# STM32F411 register map
File version: 1.5
Registers are 32-bit, read-write, reset 0x0 unless marked. A register's access mark holds for its fields unless they carry their own. Offsets are from the block's base; [hi:lo] are bit positions; {n}, {i} and the like mark numbered series.

## TIM2 — General purpose timers
Base 0x40000000
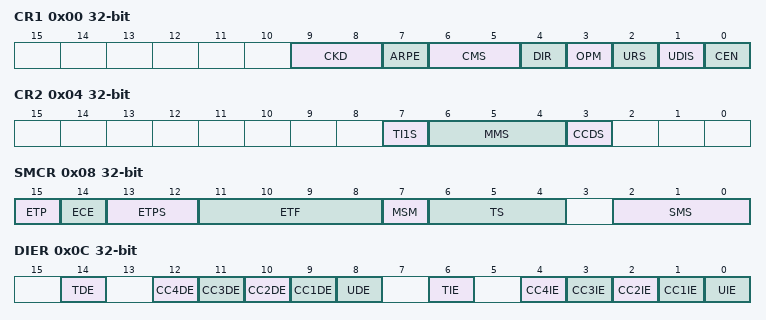
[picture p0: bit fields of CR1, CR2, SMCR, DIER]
0x00 CR1 — control register 1
  [9:8] CKD — Clock division
  [7] ARPE — Auto-reload preload enable
  [6:5] CMS — Center-aligned mode selection
  [4] DIR — Direction
  [3] OPM — One-pulse mode
  [2] URS — Update request source
  [1] UDIS — Update disable
  [0] CEN — Counter enable
0x04 CR2 — control register 2
  [7] TI1S — TI1 selection
  [6:4] MMS — Master mode selection
  [3] CCDS — Capture/compare DMA selection
0x08 SMCR — slave mode control register
  [15] ETP — External trigger polarity
  [14] ECE — External clock enable
  [13:12] ETPS — External trigger prescaler
  [11:8] ETF — External trigger filter
  [7] MSM — Master/Slave mode
  [6:4] TS — Trigger selection
  [2:0] SMS — Slave mode selection
0x0C DIER — DMA/Interrupt enable register
  [14] TDE — Trigger DMA request enable
  [n+8] CC{n}DE (n=1..4) — Capture/Compare {n} DMA request enable
  [8] UDE — Update DMA request enable
  [6] TIE — Trigger interrupt enable
  [n] CC{n}IE (n=1..4) — Capture/Compare {n} interrupt enable
  [0] UIE — Update interrupt enable
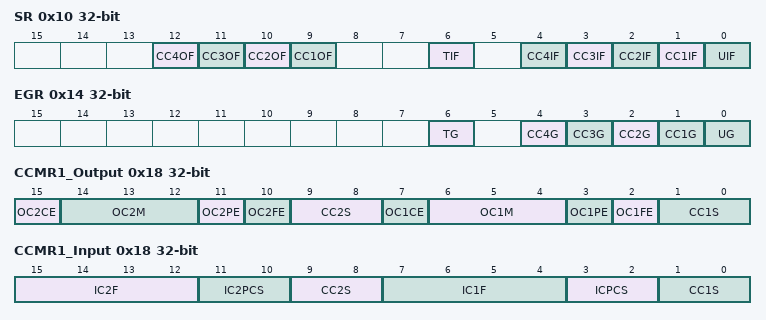
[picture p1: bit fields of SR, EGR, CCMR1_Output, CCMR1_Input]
0x10 SR — status register
  [12] CC4OF — Capture/Compare 4 overcapture flag
  [11] CC3OF — Capture/Compare 3 overcapture flag
  [10] CC2OF — Capture/compare 2 overcapture flag
  [9] CC1OF — Capture/Compare 1 overcapture flag
  [6] TIF — Trigger interrupt flag
  [4] CC4IF — Capture/Compare 4 interrupt flag
  [3] CC3IF — Capture/Compare 3 interrupt flag
  [2] CC2IF — Capture/Compare 2 interrupt flag
  [1] CC1IF — Capture/compare 1 interrupt flag
  [0] UIF — Update interrupt flag
0x14 EGR wo — event generation register
  [6] TG — Trigger generation
  [n] CC{n}G (n=1..4) — Capture/compare {n} generation
  [0] UG — Update generation
0x18 CCMR1_Output — capture/compare mode register 1 (output mode)
  [15] OC2CE, [14:12] OC2M, [11] OC2PE, [10] OC2FE, [9:8] CC2S, [7] OC1CE, [6:4] OC1M, [3] OC1PE, [2] OC1FE, [1:0] CC1S
0x18 CCMR1_Input (alternate view of CCMR1_Output) — capture/compare mode register 1 (input mode)
  [15:12] IC2F — Input capture 2 filter
  [11:10] IC2PCS — Input capture 2 prescaler
  [9:8] CC2S — Capture/Compare 2 selection
  [7:4] IC1F — Input capture 1 filter
  [3:2] ICPCS — Input capture 1 prescaler
  [1:0] CC1S — Capture/Compare 1 selection
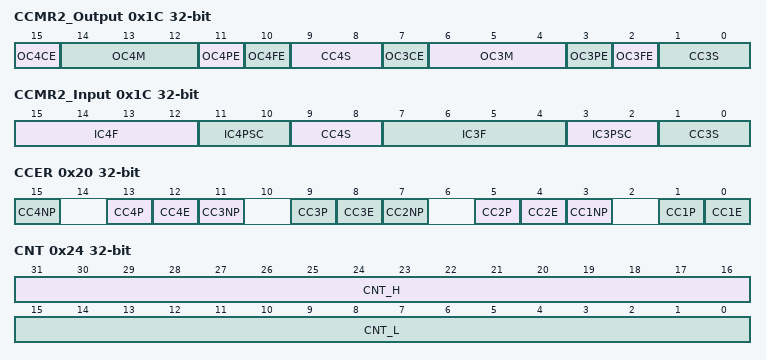
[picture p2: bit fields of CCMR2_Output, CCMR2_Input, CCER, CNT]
0x1C CCMR2_Output — capture/compare mode register 2 (output mode)
  [15] OC4CE, [14:12] OC4M, [11] OC4PE, [10] OC4FE, [9:8] CC4S, [7] OC3CE, [6:4] OC3M, [3] OC3PE, [2] OC3FE, [1:0] CC3S
0x1C CCMR2_Input (alternate view of CCMR2_Output) — capture/compare mode register 2 (input mode)
  [15:12] IC4F — Input capture 4 filter
  [11:10] IC4PSC — Input capture 4 prescaler
  [9:8] CC4S — Capture/Compare 4 selection
  [7:4] IC3F — Input capture 3 filter
  [3:2] IC3PSC — Input capture 3 prescaler
  [1:0] CC3S — Capture/compare 3 selection
0x20 CCER — capture/compare enable register
  [4n-1] CC{n}NP (n=1..4) — Capture/Compare {n} output Polarity
  [13] CC4P — Capture/Compare 3 output Polarity
  [4n-4] CC{n}E (n=1..4) — Capture/Compare {n} output enable
  [9] CC3P — Capture/Compare 3 output Polarity
  [5] CC2P — Capture/Compare 2 output Polarity
  [1] CC1P — Capture/Compare 1 output Polarity
0x24 CNT — counter
  [31:16] CNT_H — High counter value
  [15:0] CNT_L — Low counter value
0x28 PSC — prescaler
  [15:0] PSC — Prescaler value
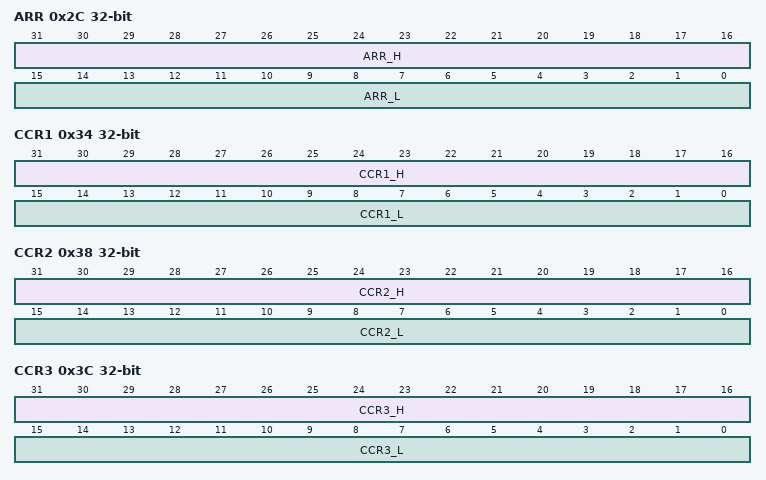
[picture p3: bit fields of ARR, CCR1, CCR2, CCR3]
0x2C ARR — auto-reload register
  [31:16] ARR_H — High Auto-reload value
  [15:0] ARR_L — Low Auto-reload value
0x34 CCR1 — capture/compare register 1
  [31:16] CCR1_H — High Capture/Compare 1 value
  [15:0] CCR1_L — Low Capture/Compare 1 value
0x38 CCR2 — capture/compare register 2
  [31:16] CCR2_H — High Capture/Compare 2 value
  [15:0] CCR2_L — Low Capture/Compare 2 value
0x3C CCR3 — capture/compare register 3
  [31:16] CCR3_H — High Capture/Compare value
  [15:0] CCR3_L — Low Capture/Compare value
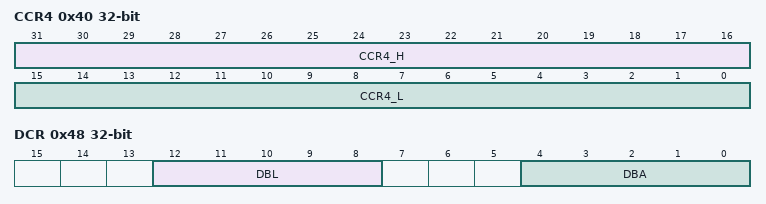
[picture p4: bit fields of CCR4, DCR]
0x40 CCR4 — capture/compare register 4
  [31:16] CCR4_H — High Capture/Compare value
  [15:0] CCR4_L — Low Capture/Compare value
0x48 DCR — DMA control register
  [12:8] DBL — DMA burst length
  [4:0] DBA — DMA base address
0x4C DMAR — DMA address for full transfer
  [15:0] DMAB — DMA register for burst accesses
0x50 OR — TIM5 option register
  [11:10] ITR1_RMP — Timer Input 4 remap

## TIM3 — General purpose timers
Base 0x40000400
Same registers: TIM4 0x40000800
Registers as TIM2, without OR.

## TIM5 — General-purpose-timers
Base 0x40000C00
Registers as TIM2; these are added or differ:
0x50 OR — TIM5 option register
  [7:6] IT4_RMP — Timer Input 4 remap

## USART1 — Universal synchronous asynchronous receiver transmitter
Base 0x40011000
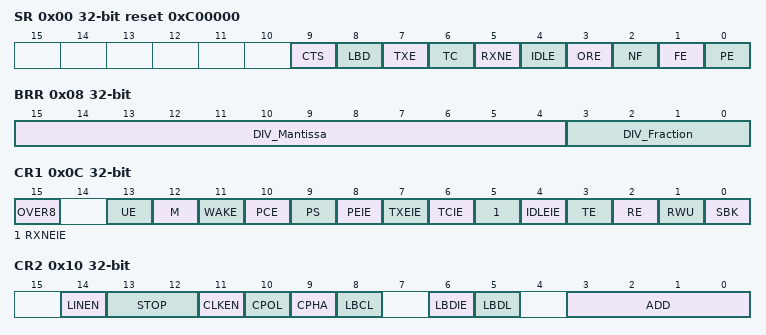
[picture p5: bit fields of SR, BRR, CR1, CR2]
0x00 SR access per field reset 0xC00000 — Status register
  [9] CTS rw — CTS flag
  [8] LBD rw — LIN break detection flag
  [7] TXE ro — Transmit data register empty
  [6] TC rw — Transmission complete
  [5] RXNE rw — Read data register not empty
  [4] IDLE ro — IDLE line detected
  [3] ORE ro — Overrun error
  [2] NF ro — Noise detected flag
  [1] FE ro — Framing error
  [0] PE ro — Parity error
0x04 DR — Data register
  [8:0] DR — Data value
0x08 BRR — Baud rate register
  [15:4] DIV_Mantissa — mantissa of USARTDIV
  [3:0] DIV_Fraction — fraction of USARTDIV
0x0C CR1 — Control register 1
  [15] OVER8 — Oversampling mode
  [13] UE — USART enable
  [12] M — Word length
  [11] WAKE — Wakeup method
  [10] PCE — Parity control enable
  [9] PS — Parity selection
  [8] PEIE — PE interrupt enable
  [7] TXEIE — TXE interrupt enable
  [6] TCIE — Transmission complete interrupt enable
  [5] RXNEIE — RXNE interrupt enable
  [4] IDLEIE — IDLE interrupt enable
  [3] TE — Transmitter enable
  [2] RE — Receiver enable
  [1] RWU — Receiver wakeup
  [0] SBK — Send break
0x10 CR2 — Control register 2
  [14] LINEN — LIN mode enable
  [13:12] STOP — STOP bits
  [11] CLKEN — Clock enable
  [10] CPOL — Clock polarity
  [9] CPHA — Clock phase
  [8] LBCL — Last bit clock pulse
  [6] LBDIE — LIN break detection interrupt enable
  [5] LBDL — lin break detection length
  [3:0] ADD — Address of the USART node
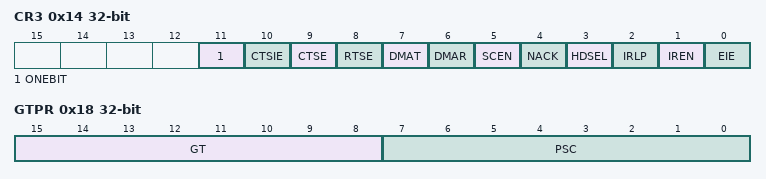
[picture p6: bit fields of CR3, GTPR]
0x14 CR3 — Control register 3
  [11] ONEBIT — One sample bit method enable
  [10] CTSIE — CTS interrupt enable
  [9] CTSE — CTS enable
  [8] RTSE — RTS enable
  [7] DMAT — DMA enable transmitter
  [6] DMAR — DMA enable receiver
  [5] SCEN — Smartcard mode enable
  [4] NACK — Smartcard NACK enable
  [3] HDSEL — Half-duplex selection
  [2] IRLP — IrDA low-power
  [1] IREN — IrDA mode enable
  [0] EIE — Error interrupt enable
0x18 GTPR — Guard time and prescaler register
  [15:8] GT — Guard time value
  [7:0] PSC — Prescaler value
